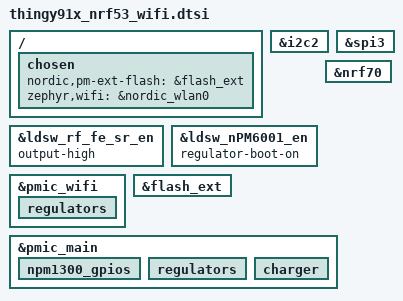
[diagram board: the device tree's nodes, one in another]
/*
 * Copyright (c) 2024 Nordic Semiconductor
 * SPDX-License-Identifier: LicenseRef-Nordic-5-Clause
 */

&i2c2 {
	status = "okay";
};

&spi3 {
	status = "okay";
};

/ {
	chosen {
		nordic,pm-ext-flash = &flash_ext;
		zephyr,wifi = &nordic_wlan0;
	};
};

/* Enable short range RF */
&ldsw_rf_fe_sr_en {
	/delete-property/ output-low;
	output-high;
};

/* Set pmic_wifi enable signal */
&ldsw_nPM6001_en {
	/delete-property/ regulator-boot-off;
	regulator-boot-on;
};

/* Enable pmic_wifi */
&pmic_wifi {
	status = "okay";
	regulators {
		status = "okay";
	};
};

/* enable nRF70 */
&nrf70 {
	status = "okay";
};

&flash_ext {
	status = "okay";
};

&pmic_main {
	status = "okay";
	npm1300_gpios {
		status = "okay";
	};
	regulators {
		status = "okay";
	};
	charger {
		status = "okay";
	};
};
